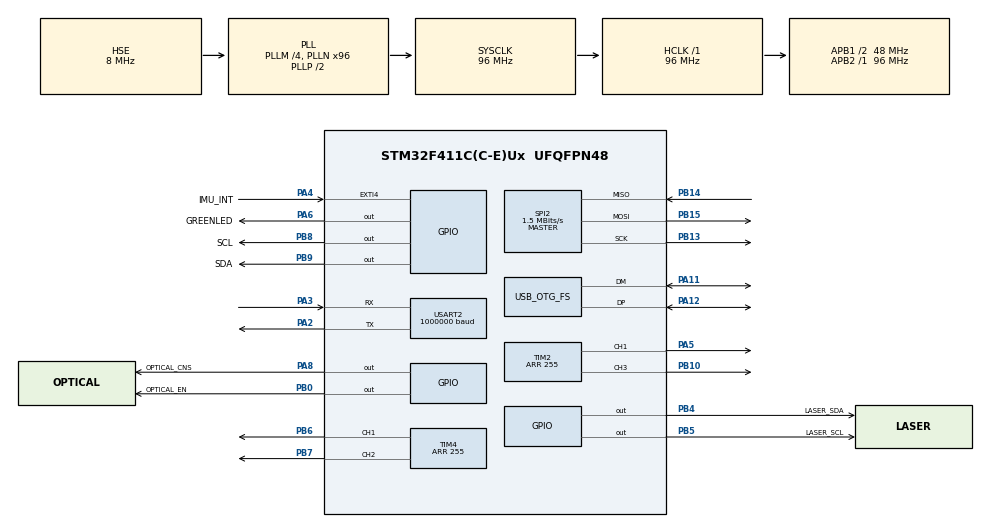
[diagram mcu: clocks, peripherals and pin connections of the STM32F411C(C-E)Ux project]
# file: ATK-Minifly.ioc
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Dma.Request0=USART2_TX
Dma.Request1=SPI2_RX
Dma.Request2=SPI2_TX
Dma.SPI2_RX.1.Direction=DMA_PERIPH_TO_MEMORY
Dma.SPI2_RX.1.FIFOMode=DMA_FIFOMODE_DISABLE
Dma.SPI2_RX.1.Instance=DMA1_Stream3
Dma.SPI2_RX.1.MemDataAlignment=DMA_MDATAALIGN_BYTE
Dma.SPI2_RX.1.MemInc=DMA_MINC_ENABLE
Dma.SPI2_RX.1.Mode=DMA_NORMAL
Dma.SPI2_RX.1.PeriphDataAlignment=DMA_PDATAALIGN_BYTE
Dma.SPI2_RX.1.PeriphInc=DMA_PINC_DISABLE
Dma.SPI2_RX.1.Priority=DMA_PRIORITY_HIGH
Dma.SPI2_TX.2.Direction=DMA_MEMORY_TO_PERIPH
Dma.SPI2_TX.2.FIFOMode=DMA_FIFOMODE_DISABLE
Dma.SPI2_TX.2.Instance=DMA1_Stream4
Dma.SPI2_TX.2.MemDataAlignment=DMA_MDATAALIGN_BYTE
Dma.SPI2_TX.2.MemInc=DMA_MINC_ENABLE
Dma.SPI2_TX.2.Mode=DMA_NORMAL
Dma.SPI2_TX.2.PeriphDataAlignment=DMA_PDATAALIGN_BYTE
Dma.SPI2_TX.2.PeriphInc=DMA_PINC_DISABLE
Dma.SPI2_TX.2.Priority=DMA_PRIORITY_HIGH
Dma.USART2_TX.0.Direction=DMA_MEMORY_TO_PERIPH
Dma.USART2_TX.0.FIFOMode=DMA_FIFOMODE_DISABLE
Dma.USART2_TX.0.Instance=DMA1_Stream6
Dma.USART2_TX.0.MemDataAlignment=DMA_MDATAALIGN_BYTE
Dma.USART2_TX.0.MemInc=DMA_MINC_ENABLE
Dma.USART2_TX.0.Mode=DMA_NORMAL
Dma.USART2_TX.0.PeriphDataAlignment=DMA_PDATAALIGN_BYTE
Dma.USART2_TX.0.PeriphInc=DMA_PINC_DISABLE
Dma.USART2_TX.0.Priority=DMA_PRIORITY_HIGH
FREERTOS.INCLUDE_vTaskDelayUntil=1
FREERTOS.Tasks01=defaultTask,0,128,StartDefaultTask,Default,NULL,Dynamic,NULL,NULL
FREERTOS.configENABLE_FPU=0
FREERTOS.configUSE_TIMERS=1
Mcu.Family=STM32F4
Mcu.Name=STM32F411C(C-E)Ux
Mcu.Package=UFQFPN48
NVIC.DMA1_Stream3_IRQn=true\:5\:0\:false\:false\:true\:true\:false\:true\:true
NVIC.DMA1_Stream4_IRQn=true\:5\:0\:false\:false\:true\:true\:false\:true\:true
NVIC.DMA1_Stream6_IRQn=true\:5\:0\:false\:false\:true\:true\:false\:true\:true
NVIC.EXTI4_IRQn=true\:5\:0\:false\:false\:true\:true\:true\:true\:true
NVIC.OTG_FS_IRQn=true\:5\:0\:false\:false\:true\:true\:false\:true\:true
NVIC.PriorityGroup=NVIC_PRIORITYGROUP_4
NVIC.SPI2_IRQn=true\:5\:0\:false\:false\:true\:true\:true\:true\:true
NVIC.USART2_IRQn=true\:5\:0\:false\:false\:true\:true\:false\:true\:true
PA11.Mode=Device_Only
PA11.Signal=USB_OTG_FS_DM
PA12.Mode=Device_Only
PA12.Signal=USB_OTG_FS_DP
PA13.Mode=Serial_Wire
PA13.Signal=SYS_JTMS-SWDIO
PA14.Mode=Serial_Wire
PA14.Signal=SYS_JTCK-SWCLK
PA2.Mode=Asynchronous
PA2.Signal=USART2_TX
PA3.Mode=Asynchronous
PA3.Signal=USART2_RX
PA4.GPIO_Label=IMU_INT
PA4.GPIO_PuPd=GPIO_PULLDOWN
PA4.Signal=GPXTI4
PA5.Signal=S_TIM2_CH1_ETR
PA6.GPIO_Label=GREENLED
PA6.Signal=GPIO_Output
PA8.GPIO_Label=OPTICAL_CNS
PA8.Signal=GPIO_Output
PB0.GPIO_Label=OPTICAL_EN
PB0.Signal=GPIO_Output
PB10.Signal=S_TIM2_CH3
PB13.GPIO_PuPd=GPIO_PULLDOWN
PB13.Mode=Full_Duplex_Master
PB13.Signal=SPI2_SCK
PB14.GPIO_PuPd=GPIO_PULLDOWN
PB14.Mode=Full_Duplex_Master
PB14.Signal=SPI2_MISO
PB15.GPIO_PuPd=GPIO_PULLDOWN
PB15.Mode=Full_Duplex_Master
PB15.Signal=SPI2_MOSI
PB4.GPIO_Label=LASER_SDA
PB4.GPIO_PuPd=GPIO_PULLUP
PB4.GPIO_Speed=GPIO_SPEED_FREQ_HIGH
PB4.Signal=GPIO_Output
PB5.GPIO_Label=LASER_SCL
PB5.GPIO_PuPd=GPIO_PULLUP
PB5.GPIO_Speed=GPIO_SPEED_FREQ_HIGH
PB5.Signal=GPIO_Output
PB6.GPIO_Speed=GPIO_SPEED_FREQ_VERY_HIGH
PB6.Signal=S_TIM4_CH1
PB7.GPIO_Speed=GPIO_SPEED_FREQ_VERY_HIGH
PB7.Signal=S_TIM4_CH2
PB8.GPIO_Label=SCL
PB8.GPIO_PuPd=GPIO_PULLUP
PB8.GPIO_Speed=GPIO_SPEED_FREQ_HIGH
PB8.Signal=GPIO_Output
PB9.GPIO_Label=SDA
PB9.GPIO_PuPd=GPIO_PULLUP
PB9.GPIO_Speed=GPIO_SPEED_FREQ_HIGH
PB9.Signal=GPIO_Output
PH0\ -\ OSC_IN.Mode=HSE-External-Oscillator
PH0\ -\ OSC_IN.Signal=RCC_OSC_IN
PH1\ -\ OSC_OUT.Mode=HSE-External-Oscillator
PH1\ -\ OSC_OUT.Signal=RCC_OSC_OUT
ProjectManager.HeapSize=0x1000
ProjectManager.StackSize=0x400
ProjectManager.TargetToolchain=MDK-ARM V5.32
RCC.48MHZClocksFreq_Value=48000000
RCC.AHBFreq_Value=96000000
RCC.APB1CLKDivider=RCC_HCLK_DIV2
RCC.APB1Freq_Value=48000000
RCC.APB1TimFreq_Value=96000000
RCC.APB2Freq_Value=96000000
RCC.APB2TimFreq_Value=96000000
RCC.CortexFreq_Value=96000000
RCC.HCLKFreq_Value=96000000
RCC.HSE_VALUE=8000000
RCC.HSI_VALUE=16000000
RCC.LSE_VALUE=32768
RCC.PLLM=4
RCC.PLLN=96
RCC.SYSCLKFreq_VALUE=96000000
RCC.SYSCLKSource=RCC_SYSCLKSOURCE_PLLCLK
RCC.VCOOutputFreq_Value=192000000
SH.S_TIM2_CH1_ETR.0=TIM2_CH1,PWM Generation1 CH1
SH.S_TIM2_CH3.0=TIM2_CH3,PWM Generation3 CH3
SH.S_TIM4_CH1.0=TIM4_CH1,PWM Generation1 CH1
SH.S_TIM4_CH2.0=TIM4_CH2,PWM Generation2 CH2
SPI2.BaudRatePrescaler=SPI_BAUDRATEPRESCALER_32
SPI2.CalculateBaudRate=1.5 MBits/s
SPI2.Direction=SPI_DIRECTION_2LINES
SPI2.Mode=SPI_MODE_MASTER
SPI2.VirtualType=VM_MASTER
TIM2.AutoReloadPreload=TIM_AUTORELOAD_PRELOAD_ENABLE
TIM2.Channel-PWM\ Generation1\ CH1=TIM_CHANNEL_1
TIM2.Channel-PWM\ Generation3\ CH3=TIM_CHANNEL_3
TIM2.Period=255
TIM4.AutoReloadPreload=TIM_AUTORELOAD_PRELOAD_ENABLE
TIM4.Channel-PWM\ Generation1\ CH1=TIM_CHANNEL_1
TIM4.Channel-PWM\ Generation2\ CH2=TIM_CHANNEL_2
TIM4.Period=255
USART2.BaudRate=1000000
USART2.VirtualMode=VM_ASYNC
USB_DEVICE.CLASS_NAME_FS=CDC
USB_DEVICE.VirtualMode=Cdc
USB_DEVICE.VirtualModeFS=Cdc_FS
USB_OTG_FS.VirtualMode=Device_Only
VP_FREERTOS_VS_CMSIS_V1.Mode=CMSIS_V1
VP_USB_DEVICE_VS_USB_DEVICE_CDC_FS.Mode=CDC_FS
board=custom

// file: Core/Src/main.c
/* USER CODE BEGIN Header */
/**
  ******************************************************************************
  * @file           : main.c
  * @brief          : Main program body
  ******************************************************************************
  * @attention
  *
  * Copyright (c) 2024 STMicroelectronics.
  * All rights reserved.
  *
  * This software is licensed under terms that can be found in the LICENSE file
  * in the root directory of this software component.
  * If no LICENSE file comes with this software, it is provided AS-IS.
  *
  ******************************************************************************
  */
/* USER CODE END Header */
#include "main.h"
#include "cmsis_os.h"
#include "usb_device.h"

/* USER CODE BEGIN Includes */
#include "embedi_system.h"
/* USER CODE END Includes */

SPI_HandleTypeDef hspi2;
DMA_HandleTypeDef hdma_spi2_rx;
DMA_HandleTypeDef hdma_spi2_tx;

TIM_HandleTypeDef htim2;
TIM_HandleTypeDef htim4;

UART_HandleTypeDef huart2;
DMA_HandleTypeDef hdma_usart2_tx;

osThreadId defaultTaskHandle;

void SystemClock_Config(void);
static void MX_GPIO_Init(void);
static void MX_DMA_Init(void);
static void MX_USART2_UART_Init(void);
static void MX_TIM2_Init(void);
static void MX_TIM4_Init(void);
static void MX_SPI2_Init(void);
void StartDefaultTask(void const * argument);

int main(void)
{

  /* USER CODE BEGIN 1 */
  //NVIC_SetVectorTable(FIRMWARE_START_ADDR, 0);
	//HAL_NVIC_SetPriorityGrouping(NVIC_PRIORITYGROUP_4);
  /* USER CODE END 1 */

  /* MCU Configuration--------------------------------------------------------*/

  /* Reset of all peripherals, Initializes the Flash interface and the Systick. */
  HAL_Init();

  /* Configure the system clock */
  SystemClock_Config();

  /* Initialize all configured peripherals */
  MX_GPIO_Init();
  MX_DMA_Init();
  MX_USART2_UART_Init();
  MX_TIM2_Init();
  MX_TIM4_Init();
  MX_SPI2_Init();
  /* USER CODE BEGIN 2 */
  embedi_system_init();
  /* USER CODE END 2 */

  /* Create the thread(s) */
  /* definition and creation of defaultTask */
  osThreadDef(defaultTask, StartDefaultTask, osPriorityNormal, 0, 128);
  defaultTaskHandle = osThreadCreate(osThread(defaultTask), NULL);

  /* Start scheduler */
  osKernelStart();

  /* We should never get here as control is now taken by the scheduler */

  /* Infinite loop */
  while (1)
  {

  }
}

void SystemClock_Config(void)
{
  RCC_OscInitTypeDef RCC_OscInitStruct = {0};
  RCC_ClkInitTypeDef RCC_ClkInitStruct = {0};

  /** Configure the main internal regulator output voltage
  */
  __HAL_RCC_PWR_CLK_ENABLE();
  __HAL_PWR_VOLTAGESCALING_CONFIG(PWR_REGULATOR_VOLTAGE_SCALE1);

  /** Initializes the RCC Oscillators according to the specified parameters
  * in the RCC_OscInitTypeDef structure.
  */
  RCC_OscInitStruct.OscillatorType = RCC_OSCILLATORTYPE_HSE;
  RCC_OscInitStruct.HSEState = RCC_HSE_ON;
  RCC_OscInitStruct.PLL.PLLState = RCC_PLL_ON;
  RCC_OscInitStruct.PLL.PLLSource = RCC_PLLSOURCE_HSE;
  RCC_OscInitStruct.PLL.PLLM = 4;
  RCC_OscInitStruct.PLL.PLLN = 96;
  RCC_OscInitStruct.PLL.PLLP = RCC_PLLP_DIV2;
  RCC_OscInitStruct.PLL.PLLQ = 4;
  if (HAL_RCC_OscConfig(&RCC_OscInitStruct) != HAL_OK)
  {
    Error_Handler();
  }

  /** Initializes the CPU, AHB and APB buses clocks
  */
  RCC_ClkInitStruct.ClockType = RCC_CLOCKTYPE_HCLK|RCC_CLOCKTYPE_SYSCLK
                              |RCC_CLOCKTYPE_PCLK1|RCC_CLOCKTYPE_PCLK2;
  RCC_ClkInitStruct.SYSCLKSource = RCC_SYSCLKSOURCE_PLLCLK;
  RCC_ClkInitStruct.AHBCLKDivider = RCC_SYSCLK_DIV1;
  RCC_ClkInitStruct.APB1CLKDivider = RCC_HCLK_DIV2;
  RCC_ClkInitStruct.APB2CLKDivider = RCC_HCLK_DIV1;

  if (HAL_RCC_ClockConfig(&RCC_ClkInitStruct, FLASH_LATENCY_3) != HAL_OK)
  {
    Error_Handler();
  }
}

static void MX_SPI2_Init(void)
{

  /* SPI2 parameter configuration*/
  hspi2.Instance = SPI2;
  hspi2.Init.Mode = SPI_MODE_MASTER;
  hspi2.Init.Direction = SPI_DIRECTION_2LINES;
  hspi2.Init.DataSize = SPI_DATASIZE_8BIT;
  hspi2.Init.CLKPolarity = SPI_POLARITY_LOW;
  hspi2.Init.CLKPhase = SPI_PHASE_1EDGE;
  hspi2.Init.NSS = SPI_NSS_SOFT;
  hspi2.Init.BaudRatePrescaler = SPI_BAUDRATEPRESCALER_32;
  hspi2.Init.FirstBit = SPI_FIRSTBIT_MSB;
  hspi2.Init.TIMode = SPI_TIMODE_DISABLE;
  hspi2.Init.CRCCalculation = SPI_CRCCALCULATION_DISABLE;
  hspi2.Init.CRCPolynomial = 10;
  if (HAL_SPI_Init(&hspi2) != HAL_OK)
  {
    Error_Handler();
  }

}

static void MX_TIM2_Init(void)
{

  TIM_MasterConfigTypeDef sMasterConfig = {0};
  TIM_OC_InitTypeDef sConfigOC = {0};

  htim2.Instance = TIM2;
  htim2.Init.Prescaler = 0;
  htim2.Init.CounterMode = TIM_COUNTERMODE_UP;
  htim2.Init.Period = 255;
  htim2.Init.ClockDivision = TIM_CLOCKDIVISION_DIV1;
  htim2.Init.AutoReloadPreload = TIM_AUTORELOAD_PRELOAD_ENABLE;
  if (HAL_TIM_PWM_Init(&htim2) != HAL_OK)
  {
    Error_Handler();
  }
  sMasterConfig.MasterOutputTrigger = TIM_TRGO_RESET;
  sMasterConfig.MasterSlaveMode = TIM_MASTERSLAVEMODE_DISABLE;
  if (HAL_TIMEx_MasterConfigSynchronization(&htim2, &sMasterConfig) != HAL_OK)
  {
    Error_Handler();
  }
  sConfigOC.OCMode = TIM_OCMODE_PWM1;
  sConfigOC.Pulse = 0;
  sConfigOC.OCPolarity = TIM_OCPOLARITY_HIGH;
  sConfigOC.OCFastMode = TIM_OCFAST_DISABLE;
  if (HAL_TIM_PWM_ConfigChannel(&htim2, &sConfigOC, TIM_CHANNEL_1) != HAL_OK)
  {
    Error_Handler();
  }
  if (HAL_TIM_PWM_ConfigChannel(&htim2, &sConfigOC, TIM_CHANNEL_3) != HAL_OK)
  {
    Error_Handler();
  }
  HAL_TIM_MspPostInit(&htim2);

}

static void MX_TIM4_Init(void)
{

  TIM_MasterConfigTypeDef sMasterConfig = {0};
  TIM_OC_InitTypeDef sConfigOC = {0};

  htim4.Instance = TIM4;
  htim4.Init.Prescaler = 0;
  htim4.Init.CounterMode = TIM_COUNTERMODE_UP;
  htim4.Init.Period = 255;
  htim4.Init.ClockDivision = TIM_CLOCKDIVISION_DIV1;
  htim4.Init.AutoReloadPreload = TIM_AUTORELOAD_PRELOAD_ENABLE;
  if (HAL_TIM_PWM_Init(&htim4) != HAL_OK)
  {
    Error_Handler();
  }
  sMasterConfig.MasterOutputTrigger = TIM_TRGO_RESET;
  sMasterConfig.MasterSlaveMode = TIM_MASTERSLAVEMODE_DISABLE;
  if (HAL_TIMEx_MasterConfigSynchronization(&htim4, &sMasterConfig) != HAL_OK)
  {
    Error_Handler();
  }
  sConfigOC.OCMode = TIM_OCMODE_PWM1;
  sConfigOC.Pulse = 0;
  sConfigOC.OCPolarity = TIM_OCPOLARITY_HIGH;
  sConfigOC.OCFastMode = TIM_OCFAST_DISABLE;
  if (HAL_TIM_PWM_ConfigChannel(&htim4, &sConfigOC, TIM_CHANNEL_1) != HAL_OK)
  {
    Error_Handler();
  }
  if (HAL_TIM_PWM_ConfigChannel(&htim4, &sConfigOC, TIM_CHANNEL_2) != HAL_OK)
  {
    Error_Handler();
  }
  HAL_TIM_MspPostInit(&htim4);

}

static void MX_USART2_UART_Init(void)
{

  huart2.Instance = USART2;
  huart2.Init.BaudRate = 1000000;
  huart2.Init.WordLength = UART_WORDLENGTH_8B;
  huart2.Init.StopBits = UART_STOPBITS_1;
  huart2.Init.Parity = UART_PARITY_NONE;
  huart2.Init.Mode = UART_MODE_TX_RX;
  huart2.Init.HwFlowCtl = UART_HWCONTROL_NONE;
  huart2.Init.OverSampling = UART_OVERSAMPLING_16;
  if (HAL_UART_Init(&huart2) != HAL_OK)
  {
    Error_Handler();
  }

}

static void MX_DMA_Init(void)
{

  /* DMA controller clock enable */
  __HAL_RCC_DMA1_CLK_ENABLE();

  /* DMA interrupt init */
  /* DMA1_Stream3_IRQn interrupt configuration */
  HAL_NVIC_SetPriority(DMA1_Stream3_IRQn, 5, 0);
  HAL_NVIC_EnableIRQ(DMA1_Stream3_IRQn);
  /* DMA1_Stream4_IRQn interrupt configuration */
  HAL_NVIC_SetPriority(DMA1_Stream4_IRQn, 5, 0);
  HAL_NVIC_EnableIRQ(DMA1_Stream4_IRQn);
  /* DMA1_Stream6_IRQn interrupt configuration */
  HAL_NVIC_SetPriority(DMA1_Stream6_IRQn, 5, 0);
  HAL_NVIC_EnableIRQ(DMA1_Stream6_IRQn);

}

static void MX_GPIO_Init(void)
{
  GPIO_InitTypeDef GPIO_InitStruct = {0};

  /* GPIO Ports Clock Enable */
  __HAL_RCC_GPIOH_CLK_ENABLE();
  __HAL_RCC_GPIOA_CLK_ENABLE();
  __HAL_RCC_GPIOB_CLK_ENABLE();

  /*Configure GPIO pin Output Level */
  HAL_GPIO_WritePin(GPIOA, GREENLED_Pin|OPTICAL_CNS_Pin, GPIO_PIN_RESET);

  /*Configure GPIO pin Output Level */
  HAL_GPIO_WritePin(GPIOB, OPTICAL_EN_Pin|LASER_SDA_Pin|LASER_SCL_Pin|SCL_Pin
                          |SDA_Pin, GPIO_PIN_RESET);

  /*Configure GPIO pin : IMU_INT_Pin */
  GPIO_InitStruct.Pin = IMU_INT_Pin;
  GPIO_InitStruct.Mode = GPIO_MODE_IT_RISING;
  GPIO_InitStruct.Pull = GPIO_PULLDOWN;
  HAL_GPIO_Init(IMU_INT_GPIO_Port, &GPIO_InitStruct);

  /*Configure GPIO pins : GREENLED_Pin OPTICAL_CNS_Pin */
  GPIO_InitStruct.Pin = GREENLED_Pin|OPTICAL_CNS_Pin;
  GPIO_InitStruct.Mode = GPIO_MODE_OUTPUT_PP;
  GPIO_InitStruct.Pull = GPIO_NOPULL;
  GPIO_InitStruct.Speed = GPIO_SPEED_FREQ_LOW;
  HAL_GPIO_Init(GPIOA, &GPIO_InitStruct);

  /*Configure GPIO pin : OPTICAL_EN_Pin */
  GPIO_InitStruct.Pin = OPTICAL_EN_Pin;
  GPIO_InitStruct.Mode = GPIO_MODE_OUTPUT_PP;
  GPIO_InitStruct.Pull = GPIO_NOPULL;
  GPIO_InitStruct.Speed = GPIO_SPEED_FREQ_LOW;
  HAL_GPIO_Init(OPTICAL_EN_GPIO_Port, &GPIO_InitStruct);

  /*Configure GPIO pins : LASER_SDA_Pin LASER_SCL_Pin SCL_Pin SDA_Pin */
  GPIO_InitStruct.Pin = LASER_SDA_Pin|LASER_SCL_Pin|SCL_Pin|SDA_Pin;
  GPIO_InitStruct.Mode = GPIO_MODE_OUTPUT_PP;
  GPIO_InitStruct.Pull = GPIO_PULLUP;
  GPIO_InitStruct.Speed = GPIO_SPEED_FREQ_HIGH;
  HAL_GPIO_Init(GPIOB, &GPIO_InitStruct);

  /* EXTI interrupt init*/
  HAL_NVIC_SetPriority(EXTI4_IRQn, 5, 0);
  HAL_NVIC_EnableIRQ(EXTI4_IRQn);

}

void StartDefaultTask(void const * argument)
{
  /* init code for USB_DEVICE */
  MX_USB_DEVICE_Init();
  for(;;)
  {
    osDelay(1);
  }
}

void Error_Handler(void)
{
  __disable_irq();
  while (1)
  {
  }
}
